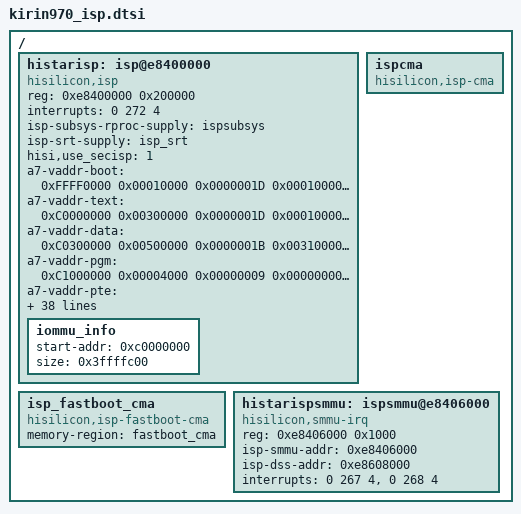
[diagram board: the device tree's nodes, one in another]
/*
 * Copyright (c) 2012-2013, The Linux Foundation. All rights reserved.
 *
 * This program is free software; you can redistribute it and/or modify
 * it under the terms of the GNU General Public License version 2 and
 * only version 2 as published by the Free Software Foundation.
 *
 * This program is distributed in the hope that it will be useful,
 * but WITHOUT ANY WARRANTY; without even the implied warranty of
 * MERCHANTABILITY or FITNESS FOR A PARTICULAR PURPOSE.  See the
 * GNU General Public License for more details.
 */
/ {
    histarisp: isp@e8400000 {
        compatible = "hisilicon,isp";
        reg = <0xe8400000 0x200000>;
        interrupts = <0 272 4>;

        status = "ok";
        isp-subsys-rproc-supply = <&ispsubsys>;
        isp-srt-supply = <&isp_srt>;
        hisi,use_secisp = <1>;

        a7-vaddr-boot       = <0xFFFF0000 0x00010000 0x0000001D 0x00010000 0x00000001 0x0 0x0>;
        a7-vaddr-text       = <0xC0000000 0x00300000 0x0000001D 0x00010000 0x00000001 0x0 0x0>;
        a7-vaddr-data       = <0xC0300000 0x00500000 0x0000001B 0x00310000 0x00000001 0x0 0x0>;
        a7-vaddr-pgm        = <0xC1000000 0x00004000 0x00000009 0x00000000 0x00000001 0x0 0x0>;
        a7-vaddr-pte        = <0xC1100000 0x00200000 0x00000009 0x00810000 0x00000001 0x0 0x0>;
        a7-vaddr-rdr        = <0xC1800000 0x00040000 0x00000013 0x00000000 0x00000001 0x0 0x0>;
        a7-vaddr-shrd       = <0xC2000000 0x00001000 0x00000003 0x0000C000 0x00000001 0x00001000 0x00001000>;
        a7-vaddr-vq         = <0xC2020000 0x00040000 0x00000003 0x00000000 0x00000001 0x0 0x0>;
        a7-vaddr-vr0        = <0xC2060000 0x00004000 0x00000003 0x00000000 0x00000001 0x0 0x0>;
        a7-vaddr-vr1        = <0xC2064000 0x00004000 0x00000003 0x00000000 0x00000001 0x0 0x0>;
        a7-vaddr-heap       = <0xC4000000 0x01800000 0x0000001B 0x00000000 0x00000001 0x0 0x0>;
        a7-vaddr-a7dyna     = <0xD1000000 0x0F000000 0x00000013 0x00000000 0x00000000 0x00003000 0x0F000000>;

        atf-shrd        = <0x00000000 0x00020000>;

        isp-remap-addr = <0x00000000>;
        isp-ipc-addr = <0xC2020000>;
        isp-iova-start = <0xC5900000>;
        isp-iova-size = <0xB700000>;
        isp-names = "ISPCPU";
        firmware-names = "isp_fw.elf";
        bootware-names = "isp_bw.elf";
        mailbox-names = "isp_mailbox";
        isp_local_timer = <19200000>;
        ispa7-default-clk = <800000000>;
        clock-num       = <3>;
        clocks          = <&clk_gate_ispcpu>, <&clk_gate_ispfunc>, <&clk_gate_ispi2c>;
        clock-names     = "ispcpu", "ispfunc", "ispi2c";
        clock-value     = <960000000 480000000 107000000>;
        isp_nosec_flag  = <0x0>;
        ispsmmu-init-byap = <0x1>;
        isp-mdc-flag    = <0x0>;
        isp-wdt-flag    = <0x0>;
        clk_flag        = <0x1>;
        clk_dvfs        = <0x0>;
        clk-dislevel    = <2>;
        clkdis-dvfs     = <400000000 267000000 107000000>;
        iommu_info{
            start-addr = <0xc0000000>;
            size = <0x3ffffc00>;
        };
    };

    ispcma {
        compatible = "hisilicon,isp-cma";
        status = "ok";
    };

    isp_fastboot_cma {
        compatible = "hisilicon,isp-fastboot-cma";
        memory-region = <&fastboot_cma>;
        status = "ok";
    };

    histarispsmmu: ispsmmu@e8406000 {
        compatible = "hisilicon,smmu-irq";
        reg = <0xe8406000 0x1000>;
            isp-smmu-addr = <0xe8406000>;
            isp-dss-addr = <0xe8608000>;
        interrupts = <0 267 4>,<0 268 4>;
        status = "ok";
    };
};
